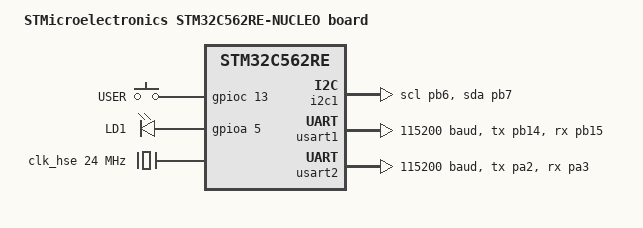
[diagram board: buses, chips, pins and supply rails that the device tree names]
/*
 * Copyright (c) 2026 STMicroelectronics
 *
 * SPDX-License-Identifier: Apache-2.0
 */

/dts-v1/;
#include <st/c5/stm32c562Xe.dtsi>
#include <st/c5/stm32c5(5-6)2r(c-e)tx-pinctrl.dtsi>
#include <zephyr/dt-bindings/input/input-event-codes.h>
#include "arduino_r3_connector.dtsi"
#include "st_morpho_connector.dtsi"

/ {
	model = "STMicroelectronics STM32C562RE-NUCLEO board";
	compatible = "st,stm32c562re-nucleo";

	#address-cells = <1>;
	#size-cells = <1>;

	chosen {
		zephyr,console = &usart2;
		zephyr,shell-uart = &usart2;
		zephyr,sram = &sram1;
		zephyr,flash = &flash0;
	};

	aliases {
		led0 = &green_led_1;
		sw0 = &user_button;
	};

	gpio_keys {
		compatible = "gpio-keys";

		user_button: button {
			label = "USER";
			gpios = <&gpioc 13 GPIO_ACTIVE_HIGH>;
			zephyr,code = <INPUT_KEY_0>;
		};
	};

	leds: leds {
		compatible = "gpio-leds";

		green_led_1: led_1 {
			gpios = <&gpioa 5 GPIO_ACTIVE_HIGH>;
			label = "LD1";
		};
	};
};

&clk_hse {
	clock-frequency = <DT_FREQ_M(24)>;
	status = "okay";
};

&clk_psis {
	clock-frequency = <DT_FREQ_M(144)>;
	status = "okay";
};

&flash0 {
	partitions {
		compatible = "fixed-partitions";
		#address-cells = <1>;
		#size-cells = <1>;

		boot_partition: partition@0 {
			label = "mcuboot";
			reg = <0x00000000 DT_SIZE_K(48)>;
		};

		slot0_partition: partition@c000 {
			label = "image-0";
			reg = <0x0000c000 DT_SIZE_K(216)>;
		};

		slot1_partition: partition@42000 {
			label = "image-1";
			reg = <0x00042000 DT_SIZE_K(224)>;
		};

		storage_partition: partition@7a000 {
			label = "storage";
			reg = <0x0007a000 DT_SIZE_K(24)>;
		};
	};
};

&i2c1 {
	pinctrl-0 = <&i2c1_scl_pb6 &i2c1_sda_pb7>;
	pinctrl-names = "default";
	status = "okay";
};

&rcc {
	clocks = <&clk_psis>;
	clock-frequency = <DT_FREQ_M(144)>;
	ahb-prescaler = <1>;
	apb1-prescaler = <2>;
	apb2-prescaler = <2>;
	apb3-prescaler = <2>;
	st,psi-frequency = <144>;
	st,psi-source = "HSE";
};

&usart1 {
	pinctrl-0 = <&usart1_tx_pb14 &usart1_rx_pb15>;
	pinctrl-names = "default";
	current-speed = <115200>;
	status = "okay";
};

&usart2 {
	pinctrl-0 = <&usart2_tx_pa2 &usart2_rx_pa3>;
	pinctrl-names = "default";
	current-speed = <115200>;
	status = "okay";
};
